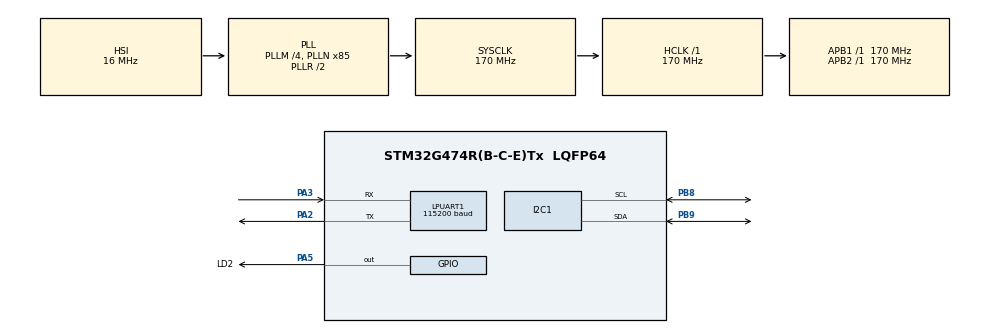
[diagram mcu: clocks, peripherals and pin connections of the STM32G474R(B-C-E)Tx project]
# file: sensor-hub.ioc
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FREERTOS.HEAP_NUMBER=4
FREERTOS.INCLUDE_eTaskGetState=1
FREERTOS.INCLUDE_pcTaskGetTaskName=1
FREERTOS.INCLUDE_uxTaskGetStackHighWaterMark=1
FREERTOS.INCLUDE_uxTaskPriorityGet=1
FREERTOS.INCLUDE_vTaskCleanUpResources=0
FREERTOS.INCLUDE_vTaskDelay=1
FREERTOS.INCLUDE_vTaskDelayUntil=1
FREERTOS.INCLUDE_vTaskDelete=1
FREERTOS.INCLUDE_vTaskPrioritySet=1
FREERTOS.INCLUDE_vTaskSuspend=1
FREERTOS.INCLUDE_xEventGroupSetBitFromISR=0
FREERTOS.INCLUDE_xQueueGetMutexHolder=1
FREERTOS.INCLUDE_xSemaphoreGetMutexHolder=1
FREERTOS.INCLUDE_xTaskAbortDelay=0
FREERTOS.INCLUDE_xTaskGetCurrentTaskHandle=1
FREERTOS.INCLUDE_xTaskGetHandle=1
FREERTOS.INCLUDE_xTaskResumeFromISR=1
FREERTOS.MEMORY_ALLOCATION=2
FREERTOS.Tasks01=defaultTask,24,128,StartDefaultTask,Default,NULL,Dynamic,NULL,NULL
FREERTOS.configCHECK_FOR_STACK_OVERFLOW=2
FREERTOS.configENABLE_BACKWARD_COMPATIBILITY=1
FREERTOS.configGENERATE_RUN_TIME_STATS=0
FREERTOS.configIDLE_SHOULD_YIELD=1
FREERTOS.configLIBRARY_LOWEST_INTERRUPT_PRIORITY=15
FREERTOS.configLIBRARY_MAX_SYSCALL_INTERRUPT_PRIORITY=5
FREERTOS.configMAX_CO_ROUTINE_PRIORITIES=2
FREERTOS.configMAX_PRIORITIES=7
FREERTOS.configMAX_TASK_NAME_LEN=16
FREERTOS.configMINIMAL_STACK_SIZE=128
FREERTOS.configQUEUE_REGISTRY_SIZE=8
FREERTOS.configRECORD_STACK_HIGH_ADDRESS=1
FREERTOS.configTICK_RATE_HZ=1000
FREERTOS.configTOTAL_HEAP_SIZE=15360
FREERTOS.configUSE_APPLICATION_TASK_TAG=0
FREERTOS.configUSE_COUNTING_SEMAPHORES=1
FREERTOS.configUSE_CO_ROUTINES=0
FREERTOS.configUSE_DAEMON_TASK_STARTUP_HOOK=0
FREERTOS.configUSE_IDLE_HOOK=0
FREERTOS.configUSE_MALLOC_FAILED_HOOK=1
FREERTOS.configUSE_MUTEXES=1
FREERTOS.configUSE_NEWLIB_REENTRANT=0
FREERTOS.configUSE_PREEMPTION=1
FREERTOS.configUSE_RECURSIVE_MUTEXES=1
FREERTOS.configUSE_STATS_FORMATTING_FUNCTIONS=0
FREERTOS.configUSE_TASK_NOTIFICATIONS=1
FREERTOS.configUSE_TICKLESS_IDLE=0
FREERTOS.configUSE_TICK_HOOK=0
FREERTOS.configUSE_TIMERS=1
FREERTOS.configUSE_TRACE_FACILITY=1
FREERTOS.copyHeapFile=1
I2C1.Timing=0x30A0A7FB
LPUART1.BaudRate=115200
LPUART1.DMADisableonRxErrorParam-Asynchronous=UART_ADVFEATURE_DMA_ENABLEONRXERROR
LPUART1.DataInvertParam-Asynchronous=UART_ADVFEATURE_DATAINV_DISABLE
LPUART1.MSBFirstParam-Asynchronous=UART_ADVFEATURE_MSBFIRST_DISABLE
LPUART1.Mode-Asynchronous=UART_MODE_TX_RX
LPUART1.OneBitSampling=UART_ONE_BIT_SAMPLE_DISABLE
LPUART1.OverrunDisableParam-Asynchronous=UART_ADVFEATURE_OVERRUN_ENABLE
LPUART1.Parity-Asynchronous=UART_PARITY_NONE
LPUART1.RxPinLevelInvertParam-Asynchronous=UART_ADVFEATURE_RXINV_DISABLE
LPUART1.StopBits-Asynchronous=UART_STOPBITS_1
LPUART1.SwapParam-Asynchronous=UART_ADVFEATURE_SWAP_DISABLE
LPUART1.TxPinLevelInvertParam-Asynchronous=UART_ADVFEATURE_TXINV_DISABLE
LPUART1.WordLength=UART_WORDLENGTH_8B
Mcu.Family=STM32G4
Mcu.Name=STM32G474R(B-C-E)Tx
Mcu.Package=LQFP64
NVIC.PriorityGroup=NVIC_PRIORITYGROUP_4
NVIC.TIM6_DAC_IRQn=true\:15\:0\:false\:false\:true\:false\:true\:true\:true
NVIC.TimeBase=TIM6_DAC_IRQn
NVIC.TimeBaseIP=TIM6
PA13.Mode=Serial_Wire
PA13.Signal=SYS_JTMS-SWDIO
PA14.Mode=Serial_Wire
PA14.Signal=SYS_JTCK-SWCLK
PA2.GPIO_PuPd=GPIO_PULLUP
PA2.Mode=Asynchronous
PA2.Signal=LPUART1_TX
PA3.GPIO_PuPd=GPIO_PULLUP
PA3.Mode=Asynchronous
PA3.Signal=LPUART1_RX
PA5.GPIO_Label=LD2
PA5.Signal=GPIO_Output
PB8.GPIO_Pu=GPIO_PULLUP
PB8.Mode=I2C
PB8.Signal=I2C1_SCL
PB9.GPIO_Pu=GPIO_PULLUP
PB9.Mode=I2C
PB9.Signal=I2C1_SDA
ProjectManager.HeapSize=0x200
ProjectManager.StackSize=0x400
ProjectManager.TargetToolchain=STM32CubeIDE
RCC.ADC12Freq_Value=170000000
RCC.ADC345Freq_Value=170000000
RCC.AHBFreq_Value=170000000
RCC.APB1Freq_Value=170000000
RCC.APB1TimFreq_Value=170000000
RCC.APB2Freq_Value=170000000
RCC.APB2TimFreq_Value=170000000
RCC.CortexFreq_Value=170000000
RCC.EXTERNAL_CLOCK_VALUE=12288000
RCC.HCLKFreq_Value=170000000
RCC.HSE_VALUE=24000000
RCC.HSI48_VALUE=48000000
RCC.HSI_VALUE=16000000
RCC.LSE_VALUE=32768
RCC.PLLM=RCC_PLLM_DIV4
RCC.PLLN=85
RCC.SYSCLKFreq_VALUE=170000000
RCC.SYSCLKSource=RCC_SYSCLKSOURCE_PLLCLK
RCC.USBFreq_Value=170000000
RCC.VCOOutputFreq_Value=340000000
VP_FREERTOS_VS_CMSIS_V2.Mode=CMSIS_V2
VP_SYS_VS_DBSignals.Mode=DisableDeadBatterySignals
VP_SYS_VS_tim6.Mode=TIM6
board=NUCLEO-G474RE

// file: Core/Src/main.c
/* USER CODE BEGIN Header */
/**
  ******************************************************************************
  * @file           : main.c
  * @brief          : Main program body
  ******************************************************************************
  */
/* USER CODE END Header */

#include "main.h"
#include "cmsis_os.h"

/* USER CODE BEGIN Includes */
#include "app.h"
/* USER CODE END Includes */

I2C_HandleTypeDef hi2c1;
UART_HandleTypeDef hlpuart1;
extern TIM_HandleTypeDef htim6;

void SystemClock_Config(void);
static void MX_GPIO_Init(void);
static void MX_LPUART1_UART_Init(void);
static void MX_I2C1_Init(void);
extern void MX_FREERTOS_Init(void);

int main(void)
{

  HAL_Init();

  SystemClock_Config();

  MX_GPIO_Init();
  MX_LPUART1_UART_Init();
  MX_I2C1_Init();

  /* USER CODE BEGIN 2 */
  app_init_early();
  /* USER CODE END 2 */

  MX_FREERTOS_Init();

  osKernelStart();

  /* We should never get here as control is now taken by the scheduler */
  while (1)
  {
  }
}

void SystemClock_Config(void)
{
  RCC_OscInitTypeDef RCC_OscInitStruct = {0};
  RCC_ClkInitTypeDef RCC_ClkInitStruct = {0};

  HAL_PWREx_ControlVoltageScaling(PWR_REGULATOR_VOLTAGE_SCALE1_BOOST);

  RCC_OscInitStruct.OscillatorType = RCC_OSCILLATORTYPE_HSI;
  RCC_OscInitStruct.HSIState = RCC_HSI_ON;
  RCC_OscInitStruct.HSICalibrationValue = RCC_HSICALIBRATION_DEFAULT;
  RCC_OscInitStruct.PLL.PLLState = RCC_PLL_ON;
  RCC_OscInitStruct.PLL.PLLSource = RCC_PLLSOURCE_HSI;
  RCC_OscInitStruct.PLL.PLLM = RCC_PLLM_DIV4;
  RCC_OscInitStruct.PLL.PLLN = 85;
  RCC_OscInitStruct.PLL.PLLP = RCC_PLLP_DIV2;
  RCC_OscInitStruct.PLL.PLLQ = RCC_PLLQ_DIV2;
  RCC_OscInitStruct.PLL.PLLR = RCC_PLLR_DIV2;
  if (HAL_RCC_OscConfig(&RCC_OscInitStruct) != HAL_OK)
  {
    Error_Handler();
  }

  RCC_ClkInitStruct.ClockType = RCC_CLOCKTYPE_HCLK | RCC_CLOCKTYPE_SYSCLK
                              | RCC_CLOCKTYPE_PCLK1 | RCC_CLOCKTYPE_PCLK2;
  RCC_ClkInitStruct.SYSCLKSource = RCC_SYSCLKSOURCE_PLLCLK;
  RCC_ClkInitStruct.AHBCLKDivider = RCC_SYSCLK_DIV1;
  RCC_ClkInitStruct.APB1CLKDivider = RCC_HCLK_DIV1;
  RCC_ClkInitStruct.APB2CLKDivider = RCC_HCLK_DIV1;
  if (HAL_RCC_ClockConfig(&RCC_ClkInitStruct, FLASH_LATENCY_4) != HAL_OK)
  {
    Error_Handler();
  }
}

static void MX_I2C1_Init(void)
{
  hi2c1.Instance = I2C1;
  hi2c1.Init.Timing = 0x30A0A7FB;
  hi2c1.Init.OwnAddress1 = 0;
  hi2c1.Init.AddressingMode = I2C_ADDRESSINGMODE_7BIT;
  hi2c1.Init.DualAddressMode = I2C_DUALADDRESS_DISABLE;
  hi2c1.Init.OwnAddress2 = 0;
  hi2c1.Init.OwnAddress2Masks = I2C_OA2_NOMASK;
  hi2c1.Init.GeneralCallMode = I2C_GENERALCALL_DISABLE;
  hi2c1.Init.NoStretchMode = I2C_NOSTRETCH_DISABLE;
  if (HAL_I2C_Init(&hi2c1) != HAL_OK)
  {
    Error_Handler();
  }

  if (HAL_I2CEx_ConfigAnalogFilter(&hi2c1, I2C_ANALOGFILTER_ENABLE) != HAL_OK)
  {
    Error_Handler();
  }

  if (HAL_I2CEx_ConfigDigitalFilter(&hi2c1, 0) != HAL_OK)
  {
    Error_Handler();
  }
}

static void MX_LPUART1_UART_Init(void)
{
  hlpuart1.Instance = LPUART1;
  hlpuart1.Init.BaudRate = 115200;
  hlpuart1.Init.WordLength = UART_WORDLENGTH_8B;
  hlpuart1.Init.StopBits = UART_STOPBITS_1;
  hlpuart1.Init.Parity = UART_PARITY_NONE;
  hlpuart1.Init.Mode = UART_MODE_TX_RX;
  hlpuart1.Init.HwFlowCtl = UART_HWCONTROL_NONE;
  hlpuart1.Init.OneBitSampling = UART_ONE_BIT_SAMPLE_DISABLE;
  hlpuart1.Init.ClockPrescaler = UART_PRESCALER_DIV1;
  hlpuart1.AdvancedInit.AdvFeatureInit = UART_ADVFEATURE_NO_INIT;
  if (HAL_UART_Init(&hlpuart1) != HAL_OK)
  {
    Error_Handler();
  }
  if (HAL_UARTEx_SetTxFifoThreshold(&hlpuart1, UART_TXFIFO_THRESHOLD_1_8) != HAL_OK)
  {
    Error_Handler();
  }
  if (HAL_UARTEx_SetRxFifoThreshold(&hlpuart1, UART_RXFIFO_THRESHOLD_1_8) != HAL_OK)
  {
    Error_Handler();
  }
  if (HAL_UARTEx_DisableFifoMode(&hlpuart1) != HAL_OK)
  {
    Error_Handler();
  }
}

static void MX_GPIO_Init(void)
{
  GPIO_InitTypeDef GPIO_InitStruct = {0};

  __HAL_RCC_GPIOA_CLK_ENABLE();
  __HAL_RCC_GPIOB_CLK_ENABLE();

  HAL_GPIO_WritePin(LD2_GPIO_Port, LD2_Pin, GPIO_PIN_RESET);

  GPIO_InitStruct.Pin = LD2_Pin;
  GPIO_InitStruct.Mode = GPIO_MODE_OUTPUT_PP;
  GPIO_InitStruct.Pull = GPIO_NOPULL;
  GPIO_InitStruct.Speed = GPIO_SPEED_FREQ_LOW;
  HAL_GPIO_Init(LD2_GPIO_Port, &GPIO_InitStruct);
}

void Error_Handler(void)
{
  __disable_irq();
  while (1)
  {
  }
}

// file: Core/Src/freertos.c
/* USER CODE BEGIN Header */
/**
  ******************************************************************************
  * @file    freertos.c
  * @brief   FreeRTOS CMSIS-RTOS2 initialization.
  ******************************************************************************
  */
/* USER CODE END Header */

#include "FreeRTOS.h"
#include "task.h"
#include "main.h"
#include "cmsis_os.h"

/* USER CODE BEGIN Includes */
#include "app.h"
/* USER CODE END Includes */

/* Definitions for defaultTask */
osThreadId_t defaultTaskHandle;
const osThreadAttr_t defaultTask_attributes = {
  .name = "defaultTask",
  .stack_size = 128 * 4,
  .priority = (osPriority_t) osPriorityNormal,
};

void StartDefaultTask(void *argument);

extern void MX_FREERTOS_Init(void); /* prototype */

void MX_FREERTOS_Init(void)
{

  /* Create the thread(s) */
  defaultTaskHandle = osThreadNew(StartDefaultTask, NULL, &defaultTask_attributes);

  /* USER CODE BEGIN RTOS_THREADS */
  app_rtos_create_tasks();
  /* USER CODE END RTOS_THREADS */

}

/**
  * @brief  Default task — just yields.
  */
void StartDefaultTask(void *argument)
{
  /* USER CODE BEGIN StartDefaultTask */
  (void)argument;
  for (;;)
  {
    osDelay(1000);
  }
  /* USER CODE END StartDefaultTask */
}

/*
 * FreeRTOS hook implementations required by FreeRTOSConfig.h
 */
void vApplicationMallocFailedHook(void)
{
  taskDISABLE_INTERRUPTS();
  for (;;) {}
}

void vApplicationStackOverflowHook(TaskHandle_t xTask, char *pcTaskName)
{
  (void)xTask;
  (void)pcTaskName;
  taskDISABLE_INTERRUPTS();
  for (;;) {}
}

/*
 * CMSIS-RTOS2 requires static allocation support.
 * Provide memory for the idle and timer tasks.
 */
static StaticTask_t xIdleTaskTCBBuffer;
static StackType_t  xIdleStack[configMINIMAL_STACK_SIZE];

void vApplicationGetIdleTaskMemory(StaticTask_t **ppxIdleTaskTCBBuffer,
                                   StackType_t **ppxIdleTaskStackBuffer,
                                   uint32_t *pulIdleTaskStackSize)
{
  *ppxIdleTaskTCBBuffer  = &xIdleTaskTCBBuffer;
  *ppxIdleTaskStackBuffer = &xIdleStack[0];
  *pulIdleTaskStackSize   = configMINIMAL_STACK_SIZE;
}

static StaticTask_t xTimerTaskTCBBuffer;
static StackType_t  xTimerStack[configTIMER_TASK_STACK_DEPTH];

void vApplicationGetTimerTaskMemory(StaticTask_t **ppxTimerTaskTCBBuffer,
                                    StackType_t **ppxTimerTaskStackBuffer,
                                    uint32_t *pulTimerTaskStackSize)
{
  *ppxTimerTaskTCBBuffer  = &xTimerTaskTCBBuffer;
  *ppxTimerTaskStackBuffer = &xTimerStack[0];
  *pulTimerTaskStackSize   = configTIMER_TASK_STACK_DEPTH;
}
